# ESP32-S3 register map
Vendor: ESPRESSIF SYSTEMS (SHANGHAI) CO., LTD.; Series: ESP32 S-Series; File version: 22
CPU: Xtensa LX7 r0p0, little endian, no MPU, FPU, 0 interrupt priority bits
Address unit: 32 bits
Registers are 32-bit, read-write, reset 0x0 unless marked. A register's access mark holds for its fields unless they carry their own. Offsets are from the block's base; [hi:lo] are bit positions.

## EXTMEM — External Memory
Base 0x600C4000
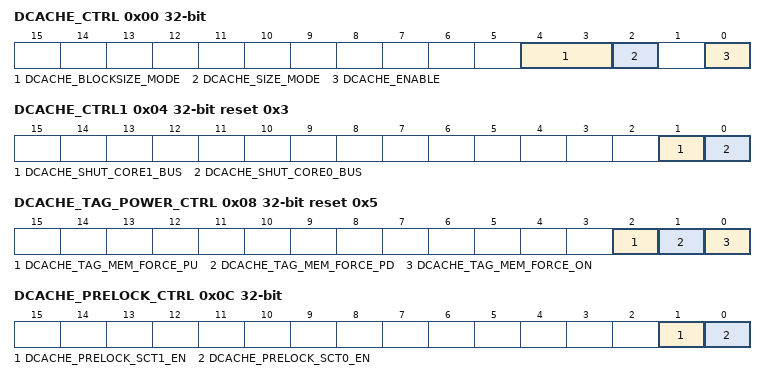
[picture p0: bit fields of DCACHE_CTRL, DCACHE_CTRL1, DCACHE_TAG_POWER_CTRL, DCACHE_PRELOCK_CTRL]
0x00 DCACHE_CTRL — ******* Description ***********
  [4:3] DCACHE_BLOCKSIZE_MODE — The bit is used to configure cache block size.0: 16 bytes, 1: 32 bytes,2: 64 bytes
  [2] DCACHE_SIZE_MODE — The bit is used to configure cache memory size.0: 32KB, 1: 64KB
  [0] DCACHE_ENABLE — The bit is used to activate the data cache. 0: disable, 1: enable
0x04 DCACHE_CTRL1 reset 0x3 — ******* Description ***********
  [1] DCACHE_SHUT_CORE1_BUS — The bit is used to disable core1 dbus, 0: enable, 1: disable
  [0] DCACHE_SHUT_CORE0_BUS — The bit is used to disable core0 dbus, 0: enable, 1: disable
0x08 DCACHE_TAG_POWER_CTRL reset 0x5 — ******* Description ***********
  [2] DCACHE_TAG_MEM_FORCE_PU — The bit is used to power dcache tag memory up, 0: follow rtc_lslp_pd, 1: power up
  [1] DCACHE_TAG_MEM_FORCE_PD — The bit is used to power dcache tag memory down, 0: follow rtc_lslp_pd, 1: power down
  [0] DCACHE_TAG_MEM_FORCE_ON — The bit is used to close clock gating of dcache tag memory. 1: close gating, 0: open clock gating.
0x0C DCACHE_PRELOCK_CTRL — ******* Description ***********
  [1] DCACHE_PRELOCK_SCT1_EN — The bit is used to enable the second section of prelock function.
  [0] DCACHE_PRELOCK_SCT0_EN — The bit is used to enable the first section of prelock function.
0x10 DCACHE_PRELOCK_SCT0_ADDR — ******* Description ***********
  [31:0] DCACHE_PRELOCK_SCT0_ADDR — The bits are used to configure the first start virtual address of data prelock, which is combined with DCACHE_PRELOCK_SCT0_SIZE_REG
0x14 DCACHE_PRELOCK_SCT1_ADDR — ******* Description ***********
  [31:0] DCACHE_PRELOCK_SCT1_ADDR — The bits are used to configure the second start virtual address of data prelock, which is combined with DCACHE_PRELOCK_SCT1_SIZE_REG
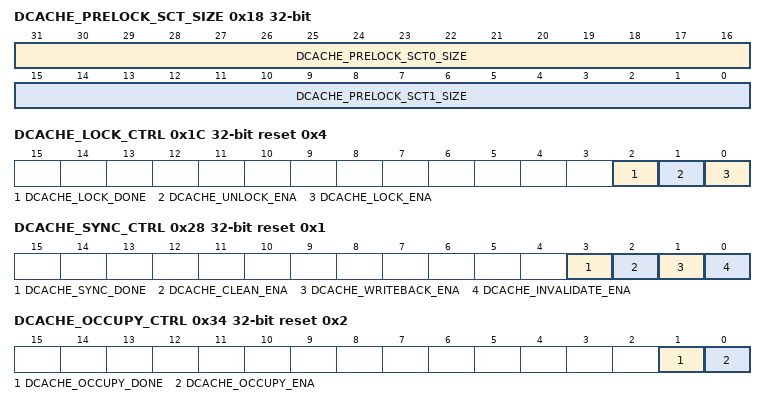
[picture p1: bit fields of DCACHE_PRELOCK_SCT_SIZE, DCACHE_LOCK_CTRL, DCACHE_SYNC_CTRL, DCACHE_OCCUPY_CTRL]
0x18 DCACHE_PRELOCK_SCT_SIZE — ******* Description ***********
  [31:16] DCACHE_PRELOCK_SCT0_SIZE — The bits are used to configure the first length of data locking, which is combined with DCACHE_PRELOCK_SCT0_ADDR_REG
  [15:0] DCACHE_PRELOCK_SCT1_SIZE — The bits are used to configure the second length of data locking, which is combined with DCACHE_PRELOCK_SCT1_ADDR_REG
0x1C DCACHE_LOCK_CTRL access per field reset 0x4 — ******* Description ***********
  [2] DCACHE_LOCK_DONE ro — The bit is used to indicate unlock/lock operation is finished.
  [1] DCACHE_UNLOCK_ENA rw — The bit is used to enable unlock operation. It will be cleared by hardware after unlock operation done.
  [0] DCACHE_LOCK_ENA rw — The bit is used to enable lock operation. It will be cleared by hardware after lock operation done.
0x20 DCACHE_LOCK_ADDR — ******* Description ***********
  [31:0] DCACHE_LOCK_ADDR — The bits are used to configure the start virtual address for lock operations. It should be combined with DCACHE_LOCK_SIZE_REG.
0x24 DCACHE_LOCK_SIZE — ******* Description ***********
  [15:0] DCACHE_LOCK_SIZE — The bits are used to configure the length for lock operations. The bits are the counts of cache block. It should be combined with DCACHE_LOCK_ADDR_REG.
0x28 DCACHE_SYNC_CTRL access per field reset 0x1 — ******* Description ***********
  [3] DCACHE_SYNC_DONE ro — The bit is used to indicate clean/writeback/invalidate operation is finished.
  [2] DCACHE_CLEAN_ENA rw — The bit is used to enable clean operation. It will be cleared by hardware after clean operation done.
  [1] DCACHE_WRITEBACK_ENA rw — The bit is used to enable writeback operation. It will be cleared by hardware after writeback operation done.
  [0] DCACHE_INVALIDATE_ENA rw — The bit is used to enable invalidate operation. It will be cleared by hardware after invalidate operation done.
0x2C DCACHE_SYNC_ADDR — ******* Description ***********
  [31:0] DCACHE_SYNC_ADDR — The bits are used to configure the start virtual address for clean operations. It should be combined with DCACHE_SYNC_SIZE_REG.
0x30 DCACHE_SYNC_SIZE — ******* Description ***********
  [22:0] DCACHE_SYNC_SIZE — The bits are used to configure the length for sync operations. The bits are the counts of cache block. It should be combined with DCACHE_SYNC_ADDR_REG.
0x34 DCACHE_OCCUPY_CTRL access per field reset 0x2 — ******* Description ***********
  [1] DCACHE_OCCUPY_DONE ro — The bit is used to indicate occupy operation is finished.
  [0] DCACHE_OCCUPY_ENA rw — The bit is used to enable occupy operation. It will be cleared by hardware after issuing Auot-Invalidate Operation.
0x38 DCACHE_OCCUPY_ADDR — ******* Description ***********
  [31:0] DCACHE_OCCUPY_ADDR — The bits are used to configure the start virtual address for occupy operation. It should be combined with DCACHE_OCCUPY_SIZE_REG.
0x3C DCACHE_OCCUPY_SIZE — ******* Description ***********
  [15:0] DCACHE_OCCUPY_SIZE — The bits are used to configure the length for occupy operation. The bits are the counts of cache block. It should be combined with DCACHE_OCCUPY_ADDR_REG.
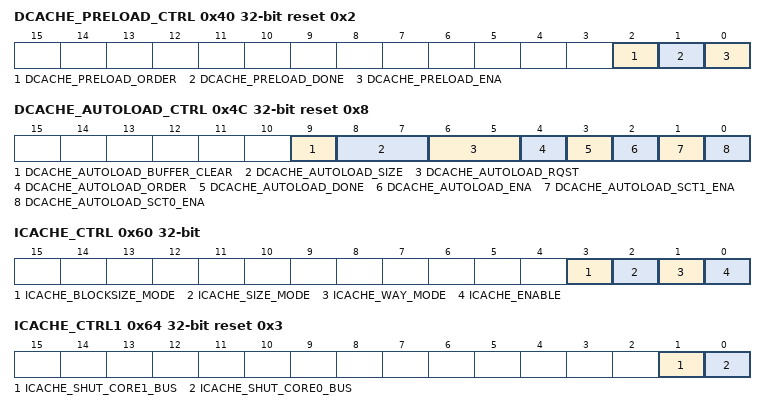
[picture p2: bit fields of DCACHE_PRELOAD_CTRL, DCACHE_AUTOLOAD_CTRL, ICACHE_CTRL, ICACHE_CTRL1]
0x40 DCACHE_PRELOAD_CTRL access per field reset 0x2 — ******* Description ***********
  [2] DCACHE_PRELOAD_ORDER rw — The bit is used to configure the direction of preload operation. 1: descending, 0: ascending.
  [1] DCACHE_PRELOAD_DONE ro — The bit is used to indicate preload operation is finished.
  [0] DCACHE_PRELOAD_ENA rw — The bit is used to enable preload operation. It will be cleared by hardware after preload operation done.
0x44 DCACHE_PRELOAD_ADDR — ******* Description ***********
  [31:0] DCACHE_PRELOAD_ADDR — The bits are used to configure the start virtual address for preload operation. It should be combined with DCACHE_PRELOAD_SIZE_REG.
0x48 DCACHE_PRELOAD_SIZE — ******* Description ***********
  [15:0] DCACHE_PRELOAD_SIZE — The bits are used to configure the length for preload operation. The bits are the counts of cache block. It should be combined with DCACHE_PRELOAD_ADDR_REG..
0x4C DCACHE_AUTOLOAD_CTRL access per field reset 0x8 — ******* Description ***********
  [9] DCACHE_AUTOLOAD_BUFFER_CLEAR rw — The bit is used to clear autoload buffer in dcache.
  [8:7] DCACHE_AUTOLOAD_SIZE rw — The bits are used to configure the numbers of the cache block for the issuing autoload operation.
  [6:5] DCACHE_AUTOLOAD_RQST rw — The bits are used to configure trigger conditions for autoload. 0/3: cache miss, 1: cache hit, 2: both cache miss and hit.
  [4] DCACHE_AUTOLOAD_ORDER rw — The bits are used to configure the direction of autoload. 1: descending, 0: ascending.
  [3] DCACHE_AUTOLOAD_DONE ro — The bit is used to indicate autoload operation is finished.
  [2] DCACHE_AUTOLOAD_ENA rw — The bit is used to enable and disable autoload operation. It is combined with dcache_autoload_done. 1: enable, 0: disable.
  [1] DCACHE_AUTOLOAD_SCT1_ENA rw — The bits are used to enable the second section for autoload operation.
  [0] DCACHE_AUTOLOAD_SCT0_ENA rw — The bits are used to enable the first section for autoload operation.
0x50 DCACHE_AUTOLOAD_SCT0_ADDR — ******* Description ***********
  [31:0] DCACHE_AUTOLOAD_SCT0_ADDR — The bits are used to configure the start virtual address of the first section for autoload operation. It should be combined with dcache_autoload_sct0_ena.
0x54 DCACHE_AUTOLOAD_SCT0_SIZE — ******* Description ***********
  [26:0] DCACHE_AUTOLOAD_SCT0_SIZE — The bits are used to configure the length of the first section for autoload operation. It should be combined with dcache_autoload_sct0_ena.
0x58 DCACHE_AUTOLOAD_SCT1_ADDR — ******* Description ***********
  [31:0] DCACHE_AUTOLOAD_SCT1_ADDR — The bits are used to configure the start virtual address of the second section for autoload operation. It should be combined with dcache_autoload_sct1_ena.
0x5C DCACHE_AUTOLOAD_SCT1_SIZE — ******* Description ***********
  [26:0] DCACHE_AUTOLOAD_SCT1_SIZE — The bits are used to configure the length of the second section for autoload operation. It should be combined with dcache_autoload_sct1_ena.
0x60 ICACHE_CTRL — ******* Description ***********
  [3] ICACHE_BLOCKSIZE_MODE — The bit is used to configure cache block size.0: 16 bytes, 1: 32 bytes
  [2] ICACHE_SIZE_MODE — The bit is used to configure cache memory size.0: 16KB, 1: 32KB
  [1] ICACHE_WAY_MODE — The bit is used to configure cache way mode.0: 4-way, 1: 8-way
  [0] ICACHE_ENABLE — The bit is used to activate the data cache. 0: disable, 1: enable
0x64 ICACHE_CTRL1 reset 0x3 — ******* Description ***********
  [1] ICACHE_SHUT_CORE1_BUS — The bit is used to disable core1 ibus, 0: enable, 1: disable
  [0] ICACHE_SHUT_CORE0_BUS — The bit is used to disable core0 ibus, 0: enable, 1: disable
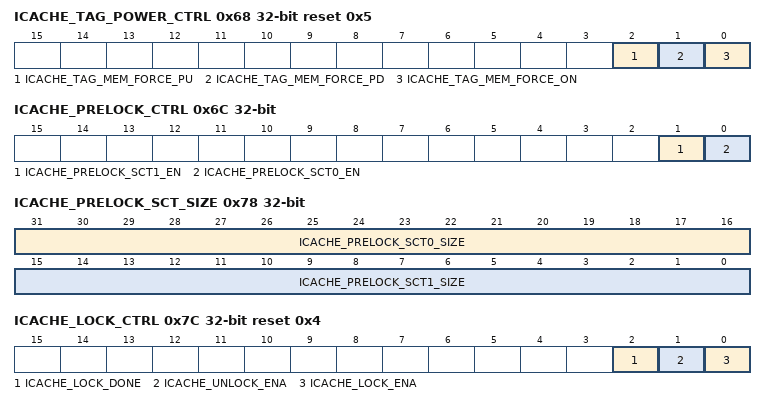
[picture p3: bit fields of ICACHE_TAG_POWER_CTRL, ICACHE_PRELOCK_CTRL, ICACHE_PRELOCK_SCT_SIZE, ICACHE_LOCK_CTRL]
0x68 ICACHE_TAG_POWER_CTRL reset 0x5 — ******* Description ***********
  [2] ICACHE_TAG_MEM_FORCE_PU — The bit is used to power icache tag memory up, 0: follow rtc_lslp, 1: power up
  [1] ICACHE_TAG_MEM_FORCE_PD — The bit is used to power icache tag memory down, 0: follow rtc_lslp, 1: power down
  [0] ICACHE_TAG_MEM_FORCE_ON — The bit is used to close clock gating of icache tag memory. 1: close gating, 0: open clock gating.
0x6C ICACHE_PRELOCK_CTRL — ******* Description ***********
  [1] ICACHE_PRELOCK_SCT1_EN — The bit is used to enable the second section of prelock function.
  [0] ICACHE_PRELOCK_SCT0_EN — The bit is used to enable the first section of prelock function.
0x70 ICACHE_PRELOCK_SCT0_ADDR — ******* Description ***********
  [31:0] ICACHE_PRELOCK_SCT0_ADDR — The bits are used to configure the first start virtual address of data prelock, which is combined with ICACHE_PRELOCK_SCT0_SIZE_REG
0x74 ICACHE_PRELOCK_SCT1_ADDR — ******* Description ***********
  [31:0] ICACHE_PRELOCK_SCT1_ADDR — The bits are used to configure the second start virtual address of data prelock, which is combined with ICACHE_PRELOCK_SCT1_SIZE_REG
0x78 ICACHE_PRELOCK_SCT_SIZE — ******* Description ***********
  [31:16] ICACHE_PRELOCK_SCT0_SIZE — The bits are used to configure the first length of data locking, which is combined with ICACHE_PRELOCK_SCT0_ADDR_REG
  [15:0] ICACHE_PRELOCK_SCT1_SIZE — The bits are used to configure the second length of data locking, which is combined with ICACHE_PRELOCK_SCT1_ADDR_REG
0x7C ICACHE_LOCK_CTRL access per field reset 0x4 — ******* Description ***********
  [2] ICACHE_LOCK_DONE ro — The bit is used to indicate unlock/lock operation is finished.
  [1] ICACHE_UNLOCK_ENA rw — The bit is used to enable unlock operation. It will be cleared by hardware after unlock operation done.
  [0] ICACHE_LOCK_ENA rw — The bit is used to enable lock operation. It will be cleared by hardware after lock operation done.
0x80 ICACHE_LOCK_ADDR — ******* Description ***********
  [31:0] ICACHE_LOCK_ADDR — The bits are used to configure the start virtual address for lock operations. It should be combined with ICACHE_LOCK_SIZE_REG.
0x84 ICACHE_LOCK_SIZE — ******* Description ***********
  [15:0] ICACHE_LOCK_SIZE — The bits are used to configure the length for lock operations. The bits are the counts of cache block. It should be combined with ICACHE_LOCK_ADDR_REG.
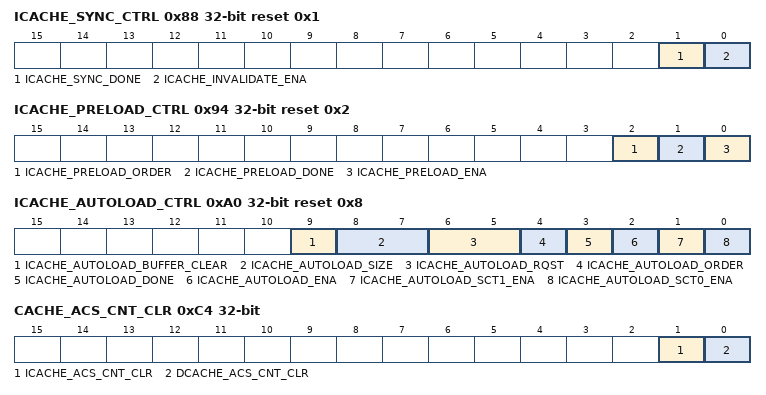
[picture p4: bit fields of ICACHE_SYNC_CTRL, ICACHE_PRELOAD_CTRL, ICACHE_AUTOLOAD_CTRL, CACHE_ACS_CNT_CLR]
0x88 ICACHE_SYNC_CTRL access per field reset 0x1 — ******* Description ***********
  [1] ICACHE_SYNC_DONE ro — The bit is used to indicate invalidate operation is finished.
  [0] ICACHE_INVALIDATE_ENA rw — The bit is used to enable invalidate operation. It will be cleared by hardware after invalidate operation done.
0x8C ICACHE_SYNC_ADDR — ******* Description ***********
  [31:0] ICACHE_SYNC_ADDR — The bits are used to configure the start virtual address for clean operations. It should be combined with ICACHE_SYNC_SIZE_REG.
0x90 ICACHE_SYNC_SIZE — ******* Description ***********
  [22:0] ICACHE_SYNC_SIZE — The bits are used to configure the length for sync operations. The bits are the counts of cache block. It should be combined with ICACHE_SYNC_ADDR_REG.
0x94 ICACHE_PRELOAD_CTRL access per field reset 0x2 — ******* Description ***********
  [2] ICACHE_PRELOAD_ORDER rw — The bit is used to configure the direction of preload operation. 1: descending, 0: ascending.
  [1] ICACHE_PRELOAD_DONE ro — The bit is used to indicate preload operation is finished.
  [0] ICACHE_PRELOAD_ENA rw — The bit is used to enable preload operation. It will be cleared by hardware after preload operation done.
0x98 ICACHE_PRELOAD_ADDR — ******* Description ***********
  [31:0] ICACHE_PRELOAD_ADDR — The bits are used to configure the start virtual address for preload operation. It should be combined with ICACHE_PRELOAD_SIZE_REG.
0x9C ICACHE_PRELOAD_SIZE — ******* Description ***********
  [15:0] ICACHE_PRELOAD_SIZE — The bits are used to configure the length for preload operation. The bits are the counts of cache block. It should be combined with ICACHE_PRELOAD_ADDR_REG..
0xA0 ICACHE_AUTOLOAD_CTRL access per field reset 0x8 — ******* Description ***********
  [9] ICACHE_AUTOLOAD_BUFFER_CLEAR rw — The bit is used to clear autoload buffer in icache.
  [8:7] ICACHE_AUTOLOAD_SIZE rw — The bits are used to configure the numbers of the cache block for the issuing autoload operation.
  [6:5] ICACHE_AUTOLOAD_RQST rw — The bits are used to configure trigger conditions for autoload. 0/3: cache miss, 1: cache hit, 2: both cache miss and hit.
  [4] ICACHE_AUTOLOAD_ORDER rw — The bits are used to configure the direction of autoload. 1: descending, 0: ascending.
  [3] ICACHE_AUTOLOAD_DONE ro — The bit is used to indicate autoload operation is finished.
  [2] ICACHE_AUTOLOAD_ENA rw — The bit is used to enable and disable autoload operation. It is combined with icache_autoload_done. 1: enable, 0: disable.
  [1] ICACHE_AUTOLOAD_SCT1_ENA rw — The bits are used to enable the second section for autoload operation.
  [0] ICACHE_AUTOLOAD_SCT0_ENA rw — The bits are used to enable the first section for autoload operation.
0xA4 ICACHE_AUTOLOAD_SCT0_ADDR — ******* Description ***********
  [31:0] ICACHE_AUTOLOAD_SCT0_ADDR — The bits are used to configure the start virtual address of the first section for autoload operation. It should be combined with icache_autoload_sct0_ena.
0xA8 ICACHE_AUTOLOAD_SCT0_SIZE — ******* Description ***********
  [26:0] ICACHE_AUTOLOAD_SCT0_SIZE — The bits are used to configure the length of the first section for autoload operation. It should be combined with icache_autoload_sct0_ena.
0xAC ICACHE_AUTOLOAD_SCT1_ADDR — ******* Description ***********
  [31:0] ICACHE_AUTOLOAD_SCT1_ADDR — The bits are used to configure the start virtual address of the second section for autoload operation. It should be combined with icache_autoload_sct1_ena.
0xB0 ICACHE_AUTOLOAD_SCT1_SIZE — ******* Description ***********
  [26:0] ICACHE_AUTOLOAD_SCT1_SIZE — The bits are used to configure the length of the second section for autoload operation. It should be combined with icache_autoload_sct1_ena.
0xB4 IBUS_TO_FLASH_START_VADDR reset 0x44000000 — ******* Description ***********
  [31:0] IBUS_TO_FLASH_START_VADDR — The bits are used to configure the start virtual address of ibus to access flash. The register is used to give constraints to ibus access counter.
0xB8 IBUS_TO_FLASH_END_VADDR reset 0x47FFFFFF — ******* Description ***********
  [31:0] IBUS_TO_FLASH_END_VADDR — The bits are used to configure the end virtual address of ibus to access flash. The register is used to give constraints to ibus access counter.
0xBC DBUS_TO_FLASH_START_VADDR — ******* Description ***********
  [31:0] DBUS_TO_FLASH_START_VADDR — The bits are used to configure the start virtual address of dbus to access flash. The register is used to give constraints to dbus access counter.
0xC0 DBUS_TO_FLASH_END_VADDR — ******* Description ***********
  [31:0] DBUS_TO_FLASH_END_VADDR — The bits are used to configure the end virtual address of dbus to access flash. The register is used to give constraints to dbus access counter.
0xC4 CACHE_ACS_CNT_CLR wo — ******* Description ***********
  [1] ICACHE_ACS_CNT_CLR — The bit is used to clear icache counter.
  [0] DCACHE_ACS_CNT_CLR — The bit is used to clear dcache counter.
0xC8 IBUS_ACS_MISS_CNT ro — ******* Description ***********
  [31:0] IBUS_ACS_MISS_CNT — The bits are used to count the number of the cache miss caused by ibus access flash/spiram.
0xCC IBUS_ACS_CNT ro — ******* Description ***********
  [31:0] IBUS_ACS_CNT — The bits are used to count the number of ibus access flash/spiram through icache.
0xD0 DBUS_ACS_FLASH_MISS_CNT ro — ******* Description ***********
  [31:0] DBUS_ACS_FLASH_MISS_CNT — The bits are used to count the number of the cache miss caused by dbus access flash.
0xD4 DBUS_ACS_SPIRAM_MISS_CNT ro — ******* Description ***********
  [31:0] DBUS_ACS_SPIRAM_MISS_CNT — The bits are used to count the number of the cache miss caused by dbus access spiram.
0xD8 DBUS_ACS_CNT ro — ******* Description ***********
  [31:0] DBUS_ACS_CNT — The bits are used to count the number of dbus access flash/spiram through dcache.
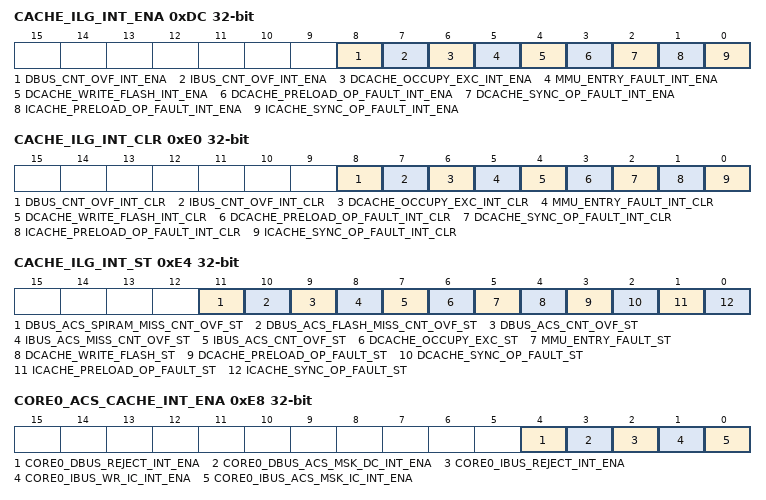
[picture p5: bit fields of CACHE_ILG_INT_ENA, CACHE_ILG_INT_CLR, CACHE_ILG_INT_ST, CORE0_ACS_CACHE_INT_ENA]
0xDC CACHE_ILG_INT_ENA — ******* Description ***********
  [8] DBUS_CNT_OVF_INT_ENA — The bit is used to enable interrupt by dbus counter overflow.
  [7] IBUS_CNT_OVF_INT_ENA — The bit is used to enable interrupt by ibus counter overflow.
  [6] DCACHE_OCCUPY_EXC_INT_ENA — The bit is used to enable interrupt by dcache trying to replace a line whose blocks all have been occupied by occupy-mode.
  [5] MMU_ENTRY_FAULT_INT_ENA — The bit is used to enable interrupt by mmu entry fault.
  [4] DCACHE_WRITE_FLASH_INT_ENA — The bit is used to enable interrupt by dcache trying to write flash.
  [3] DCACHE_PRELOAD_OP_FAULT_INT_ENA — The bit is used to enable interrupt by preload configurations fault.
  [2] DCACHE_SYNC_OP_FAULT_INT_ENA — The bit is used to enable interrupt by sync configurations fault.
  [1] ICACHE_PRELOAD_OP_FAULT_INT_ENA — The bit is used to enable interrupt by preload configurations fault.
  [0] ICACHE_SYNC_OP_FAULT_INT_ENA — The bit is used to enable interrupt by sync configurations fault.
0xE0 CACHE_ILG_INT_CLR wo — ******* Description ***********
  [8] DBUS_CNT_OVF_INT_CLR — The bit is used to clear interrupt by dbus counter overflow.
  [7] IBUS_CNT_OVF_INT_CLR — The bit is used to clear interrupt by ibus counter overflow.
  [6] DCACHE_OCCUPY_EXC_INT_CLR — The bit is used to clear interrupt by dcache trying to replace a line whose blocks all have been occupied by occupy-mode.
  [5] MMU_ENTRY_FAULT_INT_CLR — The bit is used to clear interrupt by mmu entry fault.
  [4] DCACHE_WRITE_FLASH_INT_CLR — The bit is used to clear interrupt by dcache trying to write flash.
  [3] DCACHE_PRELOAD_OP_FAULT_INT_CLR — The bit is used to clear interrupt by preload configurations fault.
  [2] DCACHE_SYNC_OP_FAULT_INT_CLR — The bit is used to clear interrupt by sync configurations fault.
  [1] ICACHE_PRELOAD_OP_FAULT_INT_CLR — The bit is used to clear interrupt by preload configurations fault.
  [0] ICACHE_SYNC_OP_FAULT_INT_CLR — The bit is used to clear interrupt by sync configurations fault.
0xE4 CACHE_ILG_INT_ST ro — ******* Description ***********
  [11] DBUS_ACS_SPIRAM_MISS_CNT_OVF_ST — The bit is used to indicate interrupt by dbus access spiram miss counter overflow.
  [10] DBUS_ACS_FLASH_MISS_CNT_OVF_ST — The bit is used to indicate interrupt by dbus access flash miss counter overflow.
  [9] DBUS_ACS_CNT_OVF_ST — The bit is used to indicate interrupt by dbus access flash/spiram counter overflow.
  [8] IBUS_ACS_MISS_CNT_OVF_ST — The bit is used to indicate interrupt by ibus access flash/spiram miss counter overflow.
  [7] IBUS_ACS_CNT_OVF_ST — The bit is used to indicate interrupt by ibus access flash/spiram counter overflow.
  [6] DCACHE_OCCUPY_EXC_ST — The bit is used to indicate interrupt by dcache trying to replace a line whose blocks all have been occupied by occupy-mode.
  [5] MMU_ENTRY_FAULT_ST — The bit is used to indicate interrupt by mmu entry fault.
  [4] DCACHE_WRITE_FLASH_ST — The bit is used to indicate interrupt by dcache trying to write flash.
  [3] DCACHE_PRELOAD_OP_FAULT_ST — The bit is used to indicate interrupt by preload configurations fault.
  [2] DCACHE_SYNC_OP_FAULT_ST — The bit is used to indicate interrupt by sync configurations fault.
  [1] ICACHE_PRELOAD_OP_FAULT_ST — The bit is used to indicate interrupt by preload configurations fault.
  [0] ICACHE_SYNC_OP_FAULT_ST — The bit is used to indicate interrupt by sync configurations fault.
0xE8 CORE0_ACS_CACHE_INT_ENA — ******* Description ***********
  [4] CORE0_DBUS_REJECT_INT_ENA — The bit is used to enable interrupt by authentication fail.
  [3] CORE0_DBUS_ACS_MSK_DC_INT_ENA — The bit is used to enable interrupt by cpu access dcache while the corresponding dbus is disabled which include speculative access.
  [2] CORE0_IBUS_REJECT_INT_ENA — The bit is used to enable interrupt by authentication fail.
  [1] CORE0_IBUS_WR_IC_INT_ENA — The bit is used to enable interrupt by ibus trying to write icache
  [0] CORE0_IBUS_ACS_MSK_IC_INT_ENA — The bit is used to enable interrupt by cpu access icache while the corresponding ibus is disabled which include speculative access.
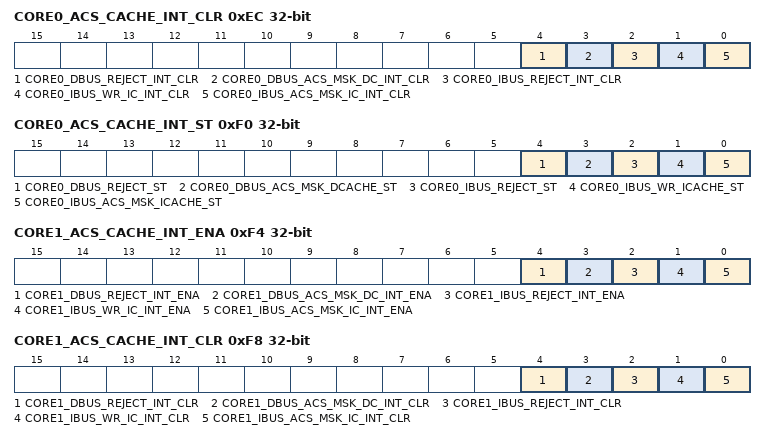
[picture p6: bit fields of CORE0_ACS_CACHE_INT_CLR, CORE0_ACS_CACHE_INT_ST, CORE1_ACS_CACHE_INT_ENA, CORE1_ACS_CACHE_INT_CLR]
0xEC CORE0_ACS_CACHE_INT_CLR wo — ******* Description ***********
  [4] CORE0_DBUS_REJECT_INT_CLR — The bit is used to clear interrupt by authentication fail.
  [3] CORE0_DBUS_ACS_MSK_DC_INT_CLR — The bit is used to clear interrupt by cpu access dcache while the corresponding dbus is disabled or dcache is disabled which include speculative access.
  [2] CORE0_IBUS_REJECT_INT_CLR — The bit is used to clear interrupt by authentication fail.
  [1] CORE0_IBUS_WR_IC_INT_CLR — The bit is used to clear interrupt by ibus trying to write icache
  [0] CORE0_IBUS_ACS_MSK_IC_INT_CLR — The bit is used to clear interrupt by cpu access icache while the corresponding ibus is disabled or icache is disabled which include speculative access.
0xF0 CORE0_ACS_CACHE_INT_ST ro — ******* Description ***********
  [4] CORE0_DBUS_REJECT_ST — The bit is used to indicate interrupt by authentication fail.
  [3] CORE0_DBUS_ACS_MSK_DCACHE_ST — The bit is used to indicate interrupt by cpu access dcache while the core0_dbus is disabled or dcache is disabled which include speculative access.
  [2] CORE0_IBUS_REJECT_ST — The bit is used to indicate interrupt by authentication fail.
  [1] CORE0_IBUS_WR_ICACHE_ST — The bit is used to indicate interrupt by ibus trying to write icache
  [0] CORE0_IBUS_ACS_MSK_ICACHE_ST — The bit is used to indicate interrupt by cpu access icache while the core0_ibus is disabled or icache is disabled which include speculative access.
0xF4 CORE1_ACS_CACHE_INT_ENA — ******* Description ***********
  [4] CORE1_DBUS_REJECT_INT_ENA — The bit is used to enable interrupt by authentication fail.
  [3] CORE1_DBUS_ACS_MSK_DC_INT_ENA — The bit is used to enable interrupt by cpu access dcache while the corresponding dbus is disabled which include speculative access.
  [2] CORE1_IBUS_REJECT_INT_ENA — The bit is used to enable interrupt by authentication fail.
  [1] CORE1_IBUS_WR_IC_INT_ENA — The bit is used to enable interrupt by ibus trying to write icache
  [0] CORE1_IBUS_ACS_MSK_IC_INT_ENA — The bit is used to enable interrupt by cpu access icache while the corresponding ibus is disabled which include speculative access.
0xF8 CORE1_ACS_CACHE_INT_CLR wo — ******* Description ***********
  [4] CORE1_DBUS_REJECT_INT_CLR — The bit is used to clear interrupt by authentication fail.
  [3] CORE1_DBUS_ACS_MSK_DC_INT_CLR — The bit is used to clear interrupt by cpu access dcache while the corresponding dbus is disabled or dcache is disabled which include speculative access.
  [2] CORE1_IBUS_REJECT_INT_CLR — The bit is used to clear interrupt by authentication fail.
  [1] CORE1_IBUS_WR_IC_INT_CLR — The bit is used to clear interrupt by ibus trying to write icache
  [0] CORE1_IBUS_ACS_MSK_IC_INT_CLR — The bit is used to clear interrupt by cpu access icache while the corresponding ibus is disabled or icache is disabled which include speculative access.
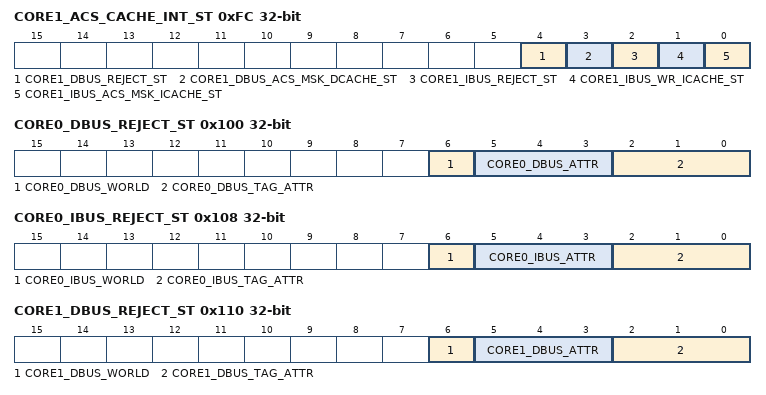
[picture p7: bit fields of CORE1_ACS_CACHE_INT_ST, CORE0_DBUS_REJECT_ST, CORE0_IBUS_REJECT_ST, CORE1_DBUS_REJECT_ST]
0xFC CORE1_ACS_CACHE_INT_ST ro — ******* Description ***********
  [4] CORE1_DBUS_REJECT_ST — The bit is used to indicate interrupt by authentication fail.
  [3] CORE1_DBUS_ACS_MSK_DCACHE_ST — The bit is used to indicate interrupt by cpu access dcache while the core1_dbus is disabled or dcache is disabled which include speculative access.
  [2] CORE1_IBUS_REJECT_ST — The bit is used to indicate interrupt by authentication fail.
  [1] CORE1_IBUS_WR_ICACHE_ST — The bit is used to indicate interrupt by ibus trying to write icache
  [0] CORE1_IBUS_ACS_MSK_ICACHE_ST — The bit is used to indicate interrupt by cpu access icache while the core1_ibus is disabled or icache is disabled which include speculative access.
0x100 CORE0_DBUS_REJECT_ST ro — ******* Description ***********
  [6] CORE0_DBUS_WORLD — The bit is used to indicate the world of CPU access dbus when authentication fail. 0: WORLD0, 1: WORLD1
  [5:3] CORE0_DBUS_ATTR — The bits are used to indicate the attribute of CPU access dbus when authentication fail. 0: invalidate, 1: execute-able, 2: read-able, 4: write-able.
  [2:0] CORE0_DBUS_TAG_ATTR — The bits are used to indicate the attribute of data from external memory when authentication fail. 0: invalidate, 1: execute-able, 2: read-able, 4: write-able.
0x104 CORE0_DBUS_REJECT_VADDR ro reset 0xFFFFFFFF — ******* Description ***********
  [31:0] CORE0_DBUS_VADDR — The bits are used to indicate the virtual address of CPU access dbus when authentication fail.
0x108 CORE0_IBUS_REJECT_ST ro — ******* Description ***********
  [6] CORE0_IBUS_WORLD — The bit is used to indicate the world of CPU access ibus when authentication fail. 0: WORLD0, 1: WORLD1
  [5:3] CORE0_IBUS_ATTR — The bits are used to indicate the attribute of CPU access ibus when authentication fail. 0: invalidate, 1: execute-able, 2: read-able
  [2:0] CORE0_IBUS_TAG_ATTR — The bits are used to indicate the attribute of data from external memory when authentication fail. 0: invalidate, 1: execute-able, 2: read-able, 4: write-able.
0x10C CORE0_IBUS_REJECT_VADDR ro reset 0xFFFFFFFF — ******* Description ***********
  [31:0] CORE0_IBUS_VADDR — The bits are used to indicate the virtual address of CPU access ibus when authentication fail.
0x110 CORE1_DBUS_REJECT_ST ro — ******* Description ***********
  [6] CORE1_DBUS_WORLD — The bit is used to indicate the world of CPU access dbus when authentication fail. 0: WORLD0, 1: WORLD1
  [5:3] CORE1_DBUS_ATTR — The bits are used to indicate the attribute of CPU access dbus when authentication fail. 0: invalidate, 1: execute-able, 2: read-able, 4: write-able.
  [2:0] CORE1_DBUS_TAG_ATTR — The bits are used to indicate the attribute of data from external memory when authentication fail. 0: invalidate, 1: execute-able, 2: read-able, 4: write-able.
0x114 CORE1_DBUS_REJECT_VADDR ro reset 0xFFFFFFFF — ******* Description ***********
  [31:0] CORE1_DBUS_VADDR — The bits are used to indicate the virtual address of CPU access dbus when authentication fail.
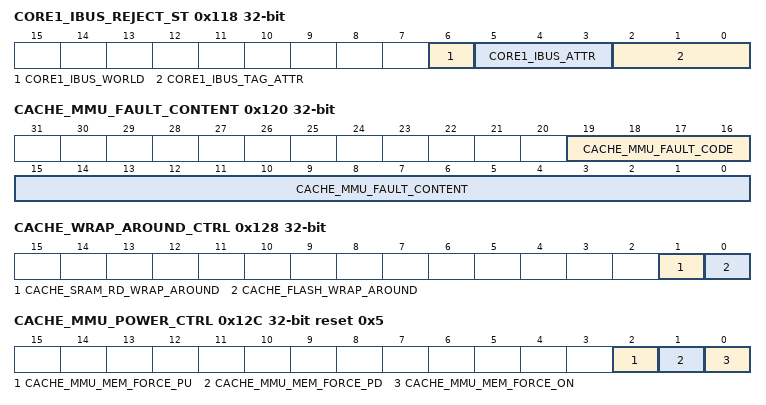
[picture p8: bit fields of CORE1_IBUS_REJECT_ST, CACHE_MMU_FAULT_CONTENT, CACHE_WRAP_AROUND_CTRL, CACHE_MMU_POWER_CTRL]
0x118 CORE1_IBUS_REJECT_ST ro — ******* Description ***********
  [6] CORE1_IBUS_WORLD — The bit is used to indicate the world of CPU access ibus when authentication fail. 0: WORLD0, 1: WORLD1
  [5:3] CORE1_IBUS_ATTR — The bits are used to indicate the attribute of CPU access ibus when authentication fail. 0: invalidate, 1: execute-able, 2: read-able
  [2:0] CORE1_IBUS_TAG_ATTR — The bits are used to indicate the attribute of data from external memory when authentication fail. 0: invalidate, 1: execute-able, 2: read-able, 4: write-able.
0x11C CORE1_IBUS_REJECT_VADDR ro reset 0xFFFFFFFF — ******* Description ***********
  [31:0] CORE1_IBUS_VADDR — The bits are used to indicate the virtual address of CPU access ibus when authentication fail.
0x120 CACHE_MMU_FAULT_CONTENT ro — ******* Description ***********
  [19:16] CACHE_MMU_FAULT_CODE — The right-most 3 bits are used to indicate the operations which cause mmu fault occurrence. 0: default, 1: cpu miss, 2: preload miss, 3: writeback, 4: cpu miss evict recovery address, 5: load miss evict recovery address, 6: external dma tx, 7: external dma rx. The most significant bit is used to indicate this operation occurs in which one icache.
  [15:0] CACHE_MMU_FAULT_CONTENT — The bits are used to indicate the content of mmu entry which cause mmu fault..
0x124 CACHE_MMU_FAULT_VADDR ro — ******* Description ***********
  [31:0] CACHE_MMU_FAULT_VADDR — The bits are used to indicate the virtual address which cause mmu fault..
0x128 CACHE_WRAP_AROUND_CTRL — ******* Description ***********
  [1] CACHE_SRAM_RD_WRAP_AROUND — The bit is used to enable wrap around mode when read data from spiram.
  [0] CACHE_FLASH_WRAP_AROUND — The bit is used to enable wrap around mode when read data from flash.
0x12C CACHE_MMU_POWER_CTRL reset 0x5 — ******* Description ***********
  [2] CACHE_MMU_MEM_FORCE_PU — The bit is used to power mmu memory down, 0: follow_rtc_lslp_pd, 1: power up
  [1] CACHE_MMU_MEM_FORCE_PD — The bit is used to power mmu memory down, 0: follow_rtc_lslp_pd, 1: power down
  [0] CACHE_MMU_MEM_FORCE_ON — The bit is used to enable clock gating to save power when access mmu memory, 0: enable, 1: disable
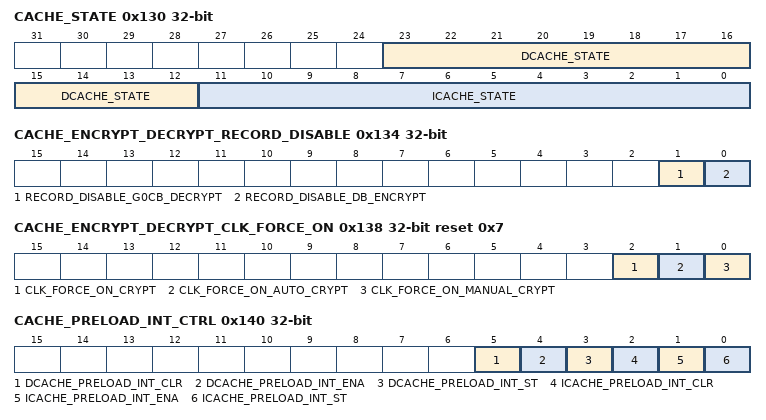
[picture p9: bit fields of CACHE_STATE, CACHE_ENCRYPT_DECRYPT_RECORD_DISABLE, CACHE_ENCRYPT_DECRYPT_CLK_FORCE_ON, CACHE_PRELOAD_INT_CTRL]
0x130 CACHE_STATE ro — ******* Description ***********
  [23:12] DCACHE_STATE — The bit is used to indicate whether dcache main fsm is in idle state or not. 1: in idle state, 0: not in idle state
  [11:0] ICACHE_STATE — The bit is used to indicate whether icache main fsm is in idle state or not. 1: in idle state, 0: not in idle state
0x134 CACHE_ENCRYPT_DECRYPT_RECORD_DISABLE — ******* Description ***********
  [1] RECORD_DISABLE_G0CB_DECRYPT — Reserved
  [0] RECORD_DISABLE_DB_ENCRYPT — Reserved
0x138 CACHE_ENCRYPT_DECRYPT_CLK_FORCE_ON reset 0x7 — ******* Description ***********
  [2] CLK_FORCE_ON_CRYPT — The bit is used to close clock gating of external memory encrypt and decrypt clock. 1: close gating, 0: open clock gating.
  [1] CLK_FORCE_ON_AUTO_CRYPT — The bit is used to close clock gating of automatic crypt clock. 1: close gating, 0: open clock gating.
  [0] CLK_FORCE_ON_MANUAL_CRYPT — The bit is used to close clock gating of manual crypt clock. 1: close gating, 0: open clock gating.
0x13C CACHE_BRIDGE_ARBITER_CTRL — ******* Description ***********
  [0] ALLOC_WB_HOLD_ARBITER — Reserved
0x140 CACHE_PRELOAD_INT_CTRL access per field — ******* Description ***********
  [5] DCACHE_PRELOAD_INT_CLR wo — The bit is used to clear the interrupt by dcache pre-load done.
  [4] DCACHE_PRELOAD_INT_ENA rw — The bit is used to enable the interrupt by dcache pre-load done.
  [3] DCACHE_PRELOAD_INT_ST ro — The bit is used to indicate the interrupt by dcache pre-load done.
  [2] ICACHE_PRELOAD_INT_CLR wo — The bit is used to clear the interrupt by icache pre-load done.
  [1] ICACHE_PRELOAD_INT_ENA rw — The bit is used to enable the interrupt by icache pre-load done.
  [0] ICACHE_PRELOAD_INT_ST ro — The bit is used to indicate the interrupt by icache pre-load done.
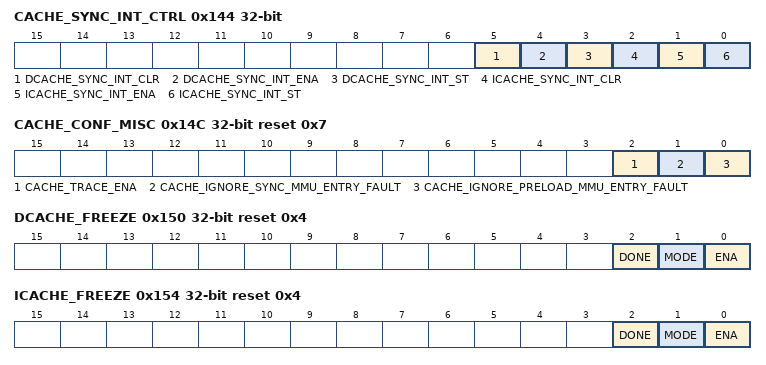
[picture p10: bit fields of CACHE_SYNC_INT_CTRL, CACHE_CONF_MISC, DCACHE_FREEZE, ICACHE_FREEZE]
0x144 CACHE_SYNC_INT_CTRL access per field — ******* Description ***********
  [5] DCACHE_SYNC_INT_CLR wo — The bit is used to clear the interrupt by dcache sync done.
  [4] DCACHE_SYNC_INT_ENA rw — The bit is used to enable the interrupt by dcache sync done.
  [3] DCACHE_SYNC_INT_ST ro — The bit is used to indicate the interrupt by dcache sync done.
  [2] ICACHE_SYNC_INT_CLR wo — The bit is used to clear the interrupt by icache sync done.
  [1] ICACHE_SYNC_INT_ENA rw — The bit is used to enable the interrupt by icache sync done.
  [0] ICACHE_SYNC_INT_ST ro — The bit is used to indicate the interrupt by icache sync done.
0x148 CACHE_MMU_OWNER — ******* Description ***********
  [23:0] CACHE_MMU_OWNER — The bits are used to specify the owner of MMU.bit0: icache, bit1: dcache, bit2: dma, bit3: reserved.
0x14C CACHE_CONF_MISC reset 0x7 — ******* Description ***********
  [2] CACHE_TRACE_ENA — The bit is used to enable cache trace function.
  [1] CACHE_IGNORE_SYNC_MMU_ENTRY_FAULT — The bit is used to disable checking mmu entry fault by sync operation.
  [0] CACHE_IGNORE_PRELOAD_MMU_ENTRY_FAULT — The bit is used to disable checking mmu entry fault by preload operation.
0x150 DCACHE_FREEZE access per field reset 0x4 — ******* Description ***********
  [2] DONE ro — The bit is used to indicate dcache freeze success
  [1] MODE rw — The bit is used to configure freeze mode, 0: assert busy if CPU miss 1: assert hit if CPU miss
  [0] ENA rw — The bit is used to enable dcache freeze mode
0x154 ICACHE_FREEZE access per field reset 0x4 — ******* Description ***********
  [2] DONE ro — The bit is used to indicate icache freeze success
  [1] MODE rw — The bit is used to configure freeze mode, 0: assert busy if CPU miss 1: assert hit if CPU miss
  [0] ENA rw — The bit is used to enable icache freeze mode
0x158 ICACHE_ATOMIC_OPERATE_ENA reset 0x1 — ******* Description ***********
  [0] ICACHE_ATOMIC_OPERATE_ENA — The bit is used to activate icache atomic operation protection. In this case, sync/lock operation can not interrupt miss-work. This feature does not work during invalidateAll operation.
0x15C DCACHE_ATOMIC_OPERATE_ENA reset 0x1 — ******* Description ***********
  [0] DCACHE_ATOMIC_OPERATE_ENA — The bit is used to activate dcache atomic operation protection. In this case, sync/lock/occupy operation can not interrupt miss-work. This feature does not work during invalidateAll operation.
0x160 CACHE_REQUEST — ******* Description ***********
  [0] BYPASS — The bit is used to disable request recording which could cause performance issue
0x164 CLOCK_GATE reset 0x1 — ******* Description ***********
  [0] CLK_EN — Reserved
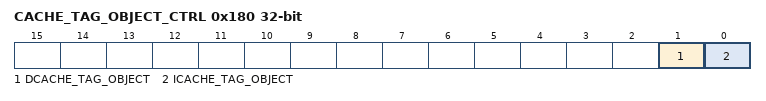
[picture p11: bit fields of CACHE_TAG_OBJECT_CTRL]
0x180 CACHE_TAG_OBJECT_CTRL — ******* Description ***********
  [1] DCACHE_TAG_OBJECT — Set this bit to set dcache tag memory as object. This bit should be onehot with the others fields inside this register.
  [0] ICACHE_TAG_OBJECT — Set this bit to set icache tag memory as object. This bit should be onehot with the others fields inside this register.
0x184 CACHE_TAG_WAY_OBJECT — ******* Description ***********
  [2:0] CACHE_TAG_WAY_OBJECT — Set this bits to select which way of the tag-object will be accessed. 0: way0, 1: way1, 2: way2, 3: way3, .., 7: way7.
0x188 CACHE_VADDR — ******* Description ***********
  [31:0] CACHE_VADDR — Those bits stores the virtual address which will decide where inside the specified tag memory object will be accessed.
0x18C CACHE_TAG_CONTENT — ******* Description ***********
  [31:0] CACHE_TAG_CONTENT — This is a constant place where we can write data to or read data from the tag memory on the specified cache.
0x3FC DATE reset 0x2012310 — ******* Description ***********
  [27:0] DATE — version information.
